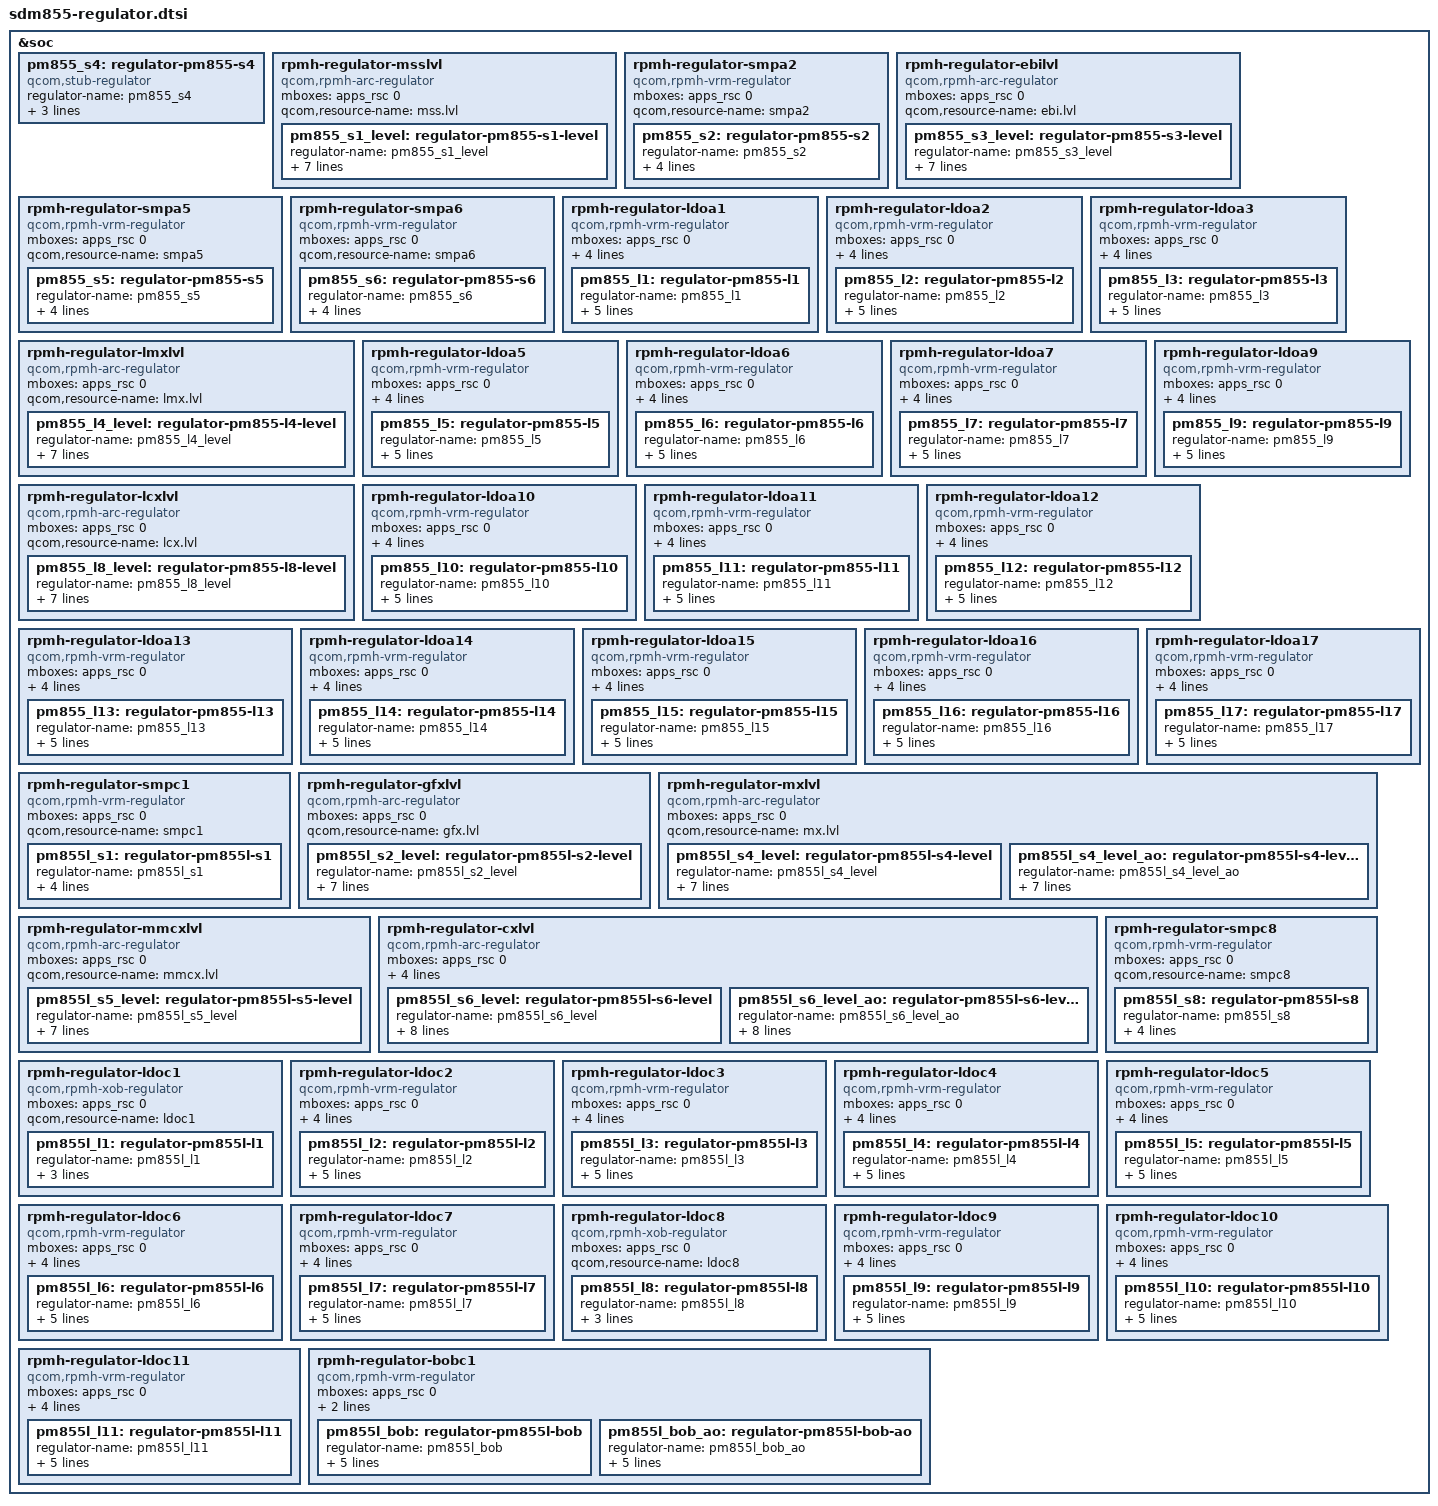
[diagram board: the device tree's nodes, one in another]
/* Copyright (c) 2017-2018, The Linux Foundation. All rights reserved.
 *
 * This program is free software; you can redistribute it and/or modify
 * it under the terms of the GNU General Public License version 2 and
 * only version 2 as published by the Free Software Foundation.
 *
 * This program is distributed in the hope that it will be useful,
 * but WITHOUT ANY WARRANTY; without even the implied warranty of
 * MERCHANTABILITY or FITNESS FOR A PARTICULAR PURPOSE.  See the
 * GNU General Public License for more details.
 */

#include <dt-bindings/regulator/qcom,rpmh-regulator.h>


&soc {
	/* Stub regulators */

	/*
	 * RPMh does not provide support for PM855 S4 because it is always-on
	 * at 1.8 V in auto mode.  Therefore, use a stub regulator for S4.
	 */
	pm855_s4: regulator-pm855-s4 {
		compatible = "qcom,stub-regulator";
		regulator-name = "pm855_s4";
		qcom,hpm-min-load = <100000>;
		regulator-min-microvolt = <1800000>;
		regulator-max-microvolt = <1800000>;
	};
};

&soc {
	/* RPMh regulators: */

	/* PM855 S1 = VDD_MODEM supply */
	rpmh-regulator-msslvl {
		compatible = "qcom,rpmh-arc-regulator";
		mboxes = <&apps_rsc 0>;
		qcom,resource-name = "mss.lvl";
		pm855_s1_level: regulator-pm855-s1-level {
			regulator-name = "pm855_s1_level";
			qcom,set = <RPMH_REGULATOR_SET_ALL>;
			regulator-min-microvolt
				= <RPMH_REGULATOR_LEVEL_RETENTION>;
			regulator-max-microvolt
				= <RPMH_REGULATOR_LEVEL_MAX>;
			qcom,init-voltage-level
				= <RPMH_REGULATOR_LEVEL_RETENTION>;
		};
	};

	rpmh-regulator-smpa2 {
		compatible = "qcom,rpmh-vrm-regulator";
		mboxes = <&apps_rsc 0>;
		qcom,resource-name = "smpa2";
		pm855_s2: regulator-pm855-s2 {
			regulator-name = "pm855_s2";
			qcom,set = <RPMH_REGULATOR_SET_ALL>;
			regulator-min-microvolt = <600000>;
			regulator-max-microvolt = <600000>;
			qcom,init-voltage = <600000>;
		};
	};

	/* PM855 S3 = VDD_EBI supply */
	rpmh-regulator-ebilvl {
		compatible = "qcom,rpmh-arc-regulator";
		mboxes = <&apps_rsc 0>;
		qcom,resource-name = "ebi.lvl";
		pm855_s3_level: regulator-pm855-s3-level {
			regulator-name = "pm855_s3_level";
			qcom,set = <RPMH_REGULATOR_SET_ALL>;
			regulator-min-microvolt
				= <RPMH_REGULATOR_LEVEL_RETENTION>;
			regulator-max-microvolt
				= <RPMH_REGULATOR_LEVEL_MAX>;
			qcom,init-voltage-level
				= <RPMH_REGULATOR_LEVEL_RETENTION>;
		};
	};

	rpmh-regulator-smpa5 {
		compatible = "qcom,rpmh-vrm-regulator";
		mboxes = <&apps_rsc 0>;
		qcom,resource-name = "smpa5";
		pm855_s5: regulator-pm855-s5 {
			regulator-name = "pm855_s5";
			qcom,set = <RPMH_REGULATOR_SET_ALL>;
			regulator-min-microvolt = <1904000>;
			regulator-max-microvolt = <2040000>;
			qcom,init-voltage = <1904000>;
		};
	};

	rpmh-regulator-smpa6 {
		compatible = "qcom,rpmh-vrm-regulator";
		mboxes = <&apps_rsc 0>;
		qcom,resource-name = "smpa6";
		pm855_s6: regulator-pm855-s6 {
			regulator-name = "pm855_s6";
			qcom,set = <RPMH_REGULATOR_SET_ALL>;
			regulator-min-microvolt = <920000>;
			regulator-max-microvolt = <1128000>;
			qcom,init-voltage = <920000>;
		};
	};

	rpmh-regulator-ldoa1 {
		compatible = "qcom,rpmh-vrm-regulator";
		mboxes = <&apps_rsc 0>;
		qcom,resource-name = "ldoa1";
		qcom,supported-modes =
			<RPMH_REGULATOR_MODE_LDO_LPM
			 RPMH_REGULATOR_MODE_LDO_HPM>;
		qcom,mode-threshold-currents = <0 1>;
		pm855_l1: regulator-pm855-l1 {
			regulator-name = "pm855_l1";
			qcom,set = <RPMH_REGULATOR_SET_ALL>;
			regulator-min-microvolt = <752000>;
			regulator-max-microvolt = <752000>;
			qcom,init-voltage = <752000>;
			qcom,init-mode = <RPMH_REGULATOR_MODE_LDO_LPM>;
		};
	};

	rpmh-regulator-ldoa2 {
		compatible = "qcom,rpmh-vrm-regulator";
		mboxes = <&apps_rsc 0>;
		qcom,resource-name = "ldoa2";
		qcom,supported-modes =
			<RPMH_REGULATOR_MODE_LDO_LPM
			 RPMH_REGULATOR_MODE_LDO_HPM>;
		qcom,mode-threshold-currents = <0 10000>;
		pm855_l2: regulator-pm855-l2 {
			regulator-name = "pm855_l2";
			qcom,set = <RPMH_REGULATOR_SET_ALL>;
			regulator-min-microvolt = <3072000>;
			regulator-max-microvolt = <3072000>;
			qcom,init-voltage = <3072000>;
			qcom,init-mode = <RPMH_REGULATOR_MODE_LDO_LPM>;
		};
	};

	rpmh-regulator-ldoa3 {
		compatible = "qcom,rpmh-vrm-regulator";
		mboxes = <&apps_rsc 0>;
		qcom,resource-name = "ldoa3";
		qcom,supported-modes =
			<RPMH_REGULATOR_MODE_LDO_LPM
			 RPMH_REGULATOR_MODE_LDO_HPM>;
		qcom,mode-threshold-currents = <0 1>;
		pm855_l3: regulator-pm855-l3 {
			regulator-name = "pm855_l3";
			qcom,set = <RPMH_REGULATOR_SET_ALL>;
			regulator-min-microvolt = <480000>;
			regulator-max-microvolt = <932000>;
			qcom,init-voltage = <480000>;
			qcom,init-mode = <RPMH_REGULATOR_MODE_LDO_LPM>;
		};
	};

	/* PM855 L4 = VDD_SSC_MX supply */
	rpmh-regulator-lmxlvl {
		compatible = "qcom,rpmh-arc-regulator";
		mboxes = <&apps_rsc 0>;
		qcom,resource-name = "lmx.lvl";
		pm855_l4_level: regulator-pm855-l4-level {
			regulator-name = "pm855_l4_level";
			qcom,set = <RPMH_REGULATOR_SET_ALL>;
			regulator-min-microvolt =
				<RPMH_REGULATOR_LEVEL_RETENTION>;
			regulator-max-microvolt =
				<RPMH_REGULATOR_LEVEL_MAX>;
			qcom,init-voltage-level
				= <RPMH_REGULATOR_LEVEL_RETENTION>;
		};
	};

	rpmh-regulator-ldoa5 {
		compatible = "qcom,rpmh-vrm-regulator";
		mboxes = <&apps_rsc 0>;
		qcom,resource-name = "ldoa5";
		qcom,supported-modes =
			<RPMH_REGULATOR_MODE_LDO_LPM
			 RPMH_REGULATOR_MODE_LDO_HPM>;
		qcom,mode-threshold-currents = <0 1>;
		pm855_l5: regulator-pm855-l5 {
			regulator-name = "pm855_l5";
			qcom,set = <RPMH_REGULATOR_SET_ALL>;
			regulator-min-microvolt = <880000>;
			regulator-max-microvolt = <880000>;
			qcom,init-voltage = <880000>;
			qcom,init-mode = <RPMH_REGULATOR_MODE_LDO_LPM>;
		};
	};

	rpmh-regulator-ldoa6 {
		compatible = "qcom,rpmh-vrm-regulator";
		mboxes = <&apps_rsc 0>;
		qcom,resource-name = "ldoa6";
		qcom,supported-modes =
			<RPMH_REGULATOR_MODE_LDO_LPM
			 RPMH_REGULATOR_MODE_LDO_HPM>;
		qcom,mode-threshold-currents = <0 10000>;
		pm855_l6: regulator-pm855-l6 {
			regulator-name = "pm855_l6";
			qcom,set = <RPMH_REGULATOR_SET_ALL>;
			regulator-min-microvolt = <1200000>;
			regulator-max-microvolt = <1200000>;
			qcom,init-voltage = <1200000>;
			qcom,init-mode = <RPMH_REGULATOR_MODE_LDO_LPM>;
		};
	};

	rpmh-regulator-ldoa7 {
		compatible = "qcom,rpmh-vrm-regulator";
		mboxes = <&apps_rsc 0>;
		qcom,resource-name = "ldoa7";
		qcom,supported-modes =
			<RPMH_REGULATOR_MODE_LDO_LPM
			 RPMH_REGULATOR_MODE_LDO_HPM>;
		qcom,mode-threshold-currents = <0 1>;
		pm855_l7: regulator-pm855-l7 {
			regulator-name = "pm855_l7";
			qcom,set = <RPMH_REGULATOR_SET_ALL>;
			regulator-min-microvolt = <1800000>;
			regulator-max-microvolt = <1800000>;
			qcom,init-voltage = <1800000>;
			qcom,init-mode = <RPMH_REGULATOR_MODE_LDO_LPM>;
		};
	};

	/* PM855 L8 = VDD_SSC_CX supply */
	rpmh-regulator-lcxlvl {
		compatible = "qcom,rpmh-arc-regulator";
		mboxes = <&apps_rsc 0>;
		qcom,resource-name = "lcx.lvl";
		pm855_l8_level: regulator-pm855-l8-level {
			regulator-name = "pm855_l8_level";
			qcom,set = <RPMH_REGULATOR_SET_ALL>;
			regulator-min-microvolt
				= <RPMH_REGULATOR_LEVEL_RETENTION>;
			regulator-max-microvolt
				= <RPMH_REGULATOR_LEVEL_MAX>;
			qcom,init-voltage-level
				= <RPMH_REGULATOR_LEVEL_RETENTION>;
		};
	};

	rpmh-regulator-ldoa9 {
		compatible = "qcom,rpmh-vrm-regulator";
		mboxes = <&apps_rsc 0>;
		qcom,resource-name = "ldoa9";
		qcom,supported-modes =
			<RPMH_REGULATOR_MODE_LDO_LPM
			 RPMH_REGULATOR_MODE_LDO_HPM>;
		qcom,mode-threshold-currents = <0 30000>;
		pm855_l9: regulator-pm855-l9 {
			regulator-name = "pm855_l9";
			qcom,set = <RPMH_REGULATOR_SET_ALL>;
			regulator-min-microvolt = <1200000>;
			regulator-max-microvolt = <1200000>;
			qcom,init-voltage = <1200000>;
			qcom,init-mode = <RPMH_REGULATOR_MODE_LDO_LPM>;
		};
	};

	rpmh-regulator-ldoa10 {
		compatible = "qcom,rpmh-vrm-regulator";
		mboxes = <&apps_rsc 0>;
		qcom,resource-name = "ldoa10";
		qcom,supported-modes =
			<RPMH_REGULATOR_MODE_LDO_LPM
			 RPMH_REGULATOR_MODE_LDO_HPM>;
		qcom,mode-threshold-currents = <0 10000>;
		pm855_l10: regulator-pm855-l10 {
			regulator-name = "pm855_l10";
			qcom,set = <RPMH_REGULATOR_SET_ALL>;
			regulator-min-microvolt = <2504000>;
			regulator-max-microvolt = <2960000>;
			qcom,init-voltage = <2504000>;
			qcom,init-mode = <RPMH_REGULATOR_MODE_LDO_LPM>;
		};
	};

	rpmh-regulator-ldoa11 {
		compatible = "qcom,rpmh-vrm-regulator";
		mboxes = <&apps_rsc 0>;
		qcom,resource-name = "ldoa11";
		qcom,supported-modes =
			<RPMH_REGULATOR_MODE_LDO_LPM
			 RPMH_REGULATOR_MODE_LDO_HPM>;
		qcom,mode-threshold-currents = <0 1>;
		pm855_l11: regulator-pm855-l11 {
			regulator-name = "pm855_l11";
			qcom,set = <RPMH_REGULATOR_SET_ALL>;
			regulator-min-microvolt = <800000>;
			regulator-max-microvolt = <800000>;
			qcom,init-voltage = <800000>;
			qcom,init-mode = <RPMH_REGULATOR_MODE_LDO_LPM>;
		};
	};

	rpmh-regulator-ldoa12 {
		compatible = "qcom,rpmh-vrm-regulator";
		mboxes = <&apps_rsc 0>;
		qcom,resource-name = "ldoa12";
		qcom,supported-modes =
			<RPMH_REGULATOR_MODE_LDO_LPM
			 RPMH_REGULATOR_MODE_LDO_HPM>;
		qcom,mode-threshold-currents = <0 1>;
		pm855_l12: regulator-pm855-l12 {
			regulator-name = "pm855_l12";
			qcom,set = <RPMH_REGULATOR_SET_ALL>;
			regulator-min-microvolt = <1800000>;
			regulator-max-microvolt = <1800000>;
			qcom,init-voltage = <1800000>;
			qcom,init-mode = <RPMH_REGULATOR_MODE_LDO_LPM>;
		};
	};

	rpmh-regulator-ldoa13 {
		compatible = "qcom,rpmh-vrm-regulator";
		mboxes = <&apps_rsc 0>;
		qcom,resource-name = "ldoa13";
		qcom,supported-modes =
			<RPMH_REGULATOR_MODE_LDO_LPM
			 RPMH_REGULATOR_MODE_LDO_HPM>;
		qcom,mode-threshold-currents = <0 1>;
		pm855_l13: regulator-pm855-l13 {
			regulator-name = "pm855_l13";
			qcom,set = <RPMH_REGULATOR_SET_ALL>;
			regulator-min-microvolt = <2704000>;
			regulator-max-microvolt = <2704000>;
			qcom,init-voltage = <2704000>;
			qcom,init-mode = <RPMH_REGULATOR_MODE_LDO_LPM>;
		};
	};

	rpmh-regulator-ldoa14 {
		compatible = "qcom,rpmh-vrm-regulator";
		mboxes = <&apps_rsc 0>;
		qcom,resource-name = "ldoa14";
		qcom,supported-modes =
			<RPMH_REGULATOR_MODE_LDO_LPM
			 RPMH_REGULATOR_MODE_LDO_HPM>;
		qcom,mode-threshold-currents = <0 10000>;
		pm855_l14: regulator-pm855-l14 {
			regulator-name = "pm855_l14";
			qcom,set = <RPMH_REGULATOR_SET_ALL>;
			regulator-min-microvolt = <1800000>;
			regulator-max-microvolt = <1880000>;
			qcom,init-voltage = <1800000>;
			qcom,init-mode = <RPMH_REGULATOR_MODE_LDO_LPM>;
		};
	};

	rpmh-regulator-ldoa15 {
		compatible = "qcom,rpmh-vrm-regulator";
		mboxes = <&apps_rsc 0>;
		qcom,resource-name = "ldoa15";
		qcom,supported-modes =
			<RPMH_REGULATOR_MODE_LDO_LPM
			 RPMH_REGULATOR_MODE_LDO_HPM>;
		qcom,mode-threshold-currents = <0 1>;
		pm855_l15: regulator-pm855-l15 {
			regulator-name = "pm855_l15";
			qcom,set = <RPMH_REGULATOR_SET_ALL>;
			regulator-min-microvolt = <1704000>;
			regulator-max-microvolt = <1704000>;
			qcom,init-voltage = <1704000>;
			qcom,init-mode = <RPMH_REGULATOR_MODE_LDO_LPM>;
		};
	};

	rpmh-regulator-ldoa16 {
		compatible = "qcom,rpmh-vrm-regulator";
		mboxes = <&apps_rsc 0>;
		qcom,resource-name = "ldoa16";
		qcom,supported-modes =
			<RPMH_REGULATOR_MODE_LDO_LPM
			 RPMH_REGULATOR_MODE_LDO_HPM>;
		qcom,mode-threshold-currents = <0 1>;
		pm855_l16: regulator-pm855-l16 {
			regulator-name = "pm855_l16";
			qcom,set = <RPMH_REGULATOR_SET_ALL>;
			regulator-min-microvolt = <2704000>;
			regulator-max-microvolt = <2960000>;
			qcom,init-voltage = <2704000>;
			qcom,init-mode = <RPMH_REGULATOR_MODE_LDO_LPM>;
		};
	};

	rpmh-regulator-ldoa17 {
		compatible = "qcom,rpmh-vrm-regulator";
		mboxes = <&apps_rsc 0>;
		qcom,resource-name = "ldoa17";
		qcom,supported-modes =
			<RPMH_REGULATOR_MODE_LDO_LPM
			 RPMH_REGULATOR_MODE_LDO_HPM>;
		qcom,mode-threshold-currents = <0 1>;
		pm855_l17: regulator-pm855-l17 {
			regulator-name = "pm855_l17";
			qcom,set = <RPMH_REGULATOR_SET_ALL>;
			regulator-min-microvolt = <2856000>;
			regulator-max-microvolt = <3008000>;
			qcom,init-voltage = <2856000>;
			qcom,init-mode = <RPMH_REGULATOR_MODE_LDO_LPM>;
		};
	};

	rpmh-regulator-smpc1 {
		compatible = "qcom,rpmh-vrm-regulator";
		mboxes = <&apps_rsc 0>;
		qcom,resource-name = "smpc1";
		pm855l_s1: regulator-pm855l-s1 {
			regulator-name = "pm855l_s1";
			qcom,set = <RPMH_REGULATOR_SET_ALL>;
			regulator-min-microvolt = <1128000>;
			regulator-max-microvolt = <1128000>;
			qcom,init-voltage = <1128000>;
		};
	};

	/* PM855L S2 + S3 = 2 phase VDD_GFX supply */
	rpmh-regulator-gfxlvl {
		compatible = "qcom,rpmh-arc-regulator";
		mboxes = <&apps_rsc 0>;
		qcom,resource-name = "gfx.lvl";
		pm855l_s2_level: regulator-pm855l-s2-level {
			regulator-name = "pm855l_s2_level";
			qcom,set = <RPMH_REGULATOR_SET_ALL>;
			regulator-min-microvolt
				= <RPMH_REGULATOR_LEVEL_RETENTION>;
			regulator-max-microvolt
				= <RPMH_REGULATOR_LEVEL_MAX>;
			qcom,init-voltage-level
				= <RPMH_REGULATOR_LEVEL_RETENTION>;
		};
	};

	/* PM855L S4 = VDD_MX supply */
	rpmh-regulator-mxlvl {
		compatible = "qcom,rpmh-arc-regulator";
		mboxes = <&apps_rsc 0>;
		qcom,resource-name = "mx.lvl";
		pm855l_s4_level: regulator-pm855l-s4-level {
			regulator-name = "pm855l_s4_level";
			qcom,set = <RPMH_REGULATOR_SET_ALL>;
			regulator-min-microvolt
				= <RPMH_REGULATOR_LEVEL_RETENTION>;
			regulator-max-microvolt
				= <RPMH_REGULATOR_LEVEL_MAX>;
			qcom,init-voltage-level
				= <RPMH_REGULATOR_LEVEL_RETENTION>;
		};

		pm855l_s4_level_ao: regulator-pm855l-s4-level-ao {
			regulator-name = "pm855l_s4_level_ao";
			qcom,set = <RPMH_REGULATOR_SET_ACTIVE>;
			regulator-min-microvolt
				= <RPMH_REGULATOR_LEVEL_RETENTION>;
			regulator-max-microvolt
				= <RPMH_REGULATOR_LEVEL_MAX>;
			qcom,init-voltage-level
				= <RPMH_REGULATOR_LEVEL_RETENTION>;
		};
	};

	/* PM855L S5 = VDD_MM_CX supply */
	rpmh-regulator-mmcxlvl {
		compatible = "qcom,rpmh-arc-regulator";
		mboxes = <&apps_rsc 0>;
		qcom,resource-name = "mmcx.lvl";
		pm855l_s5_level: regulator-pm855l-s5-level {
			regulator-name = "pm855l_s5_level";
			qcom,set = <RPMH_REGULATOR_SET_ALL>;
			regulator-min-microvolt
				= <RPMH_REGULATOR_LEVEL_LOW_SVS>;
			regulator-max-microvolt
				= <RPMH_REGULATOR_LEVEL_MAX>;
			qcom,init-voltage-level
				= <RPMH_REGULATOR_LEVEL_LOW_SVS>;
		};
	};

	/* PM855L S6 + S7 = VDD_CX supply */
	rpmh-regulator-cxlvl {
		compatible = "qcom,rpmh-arc-regulator";
		mboxes = <&apps_rsc 0>;
		qcom,resource-name = "cx.lvl";
		pm855l_s6_level-parent-supply = <&pm855l_s4_level>;
		pm855l_s6_level_ao-parent-supply = <&pm855l_s4_level_ao>;
		pm855l_s6_level: regulator-pm855l-s6-level {
			regulator-name = "pm855l_s6_level";
			qcom,set = <RPMH_REGULATOR_SET_ALL>;
			regulator-min-microvolt
				= <RPMH_REGULATOR_LEVEL_RETENTION>;
			regulator-max-microvolt
				= <RPMH_REGULATOR_LEVEL_MAX>;
			qcom,init-voltage-level
				= <RPMH_REGULATOR_LEVEL_RETENTION>;
			qcom,min-dropout-voltage-level = <(-1)>;
		};

		pm855l_s6_level_ao: regulator-pm855l-s6-level-ao {
			regulator-name = "pm855l_s6_level_ao";
			qcom,set = <RPMH_REGULATOR_SET_ACTIVE>;
			regulator-min-microvolt
				= <RPMH_REGULATOR_LEVEL_RETENTION>;
			regulator-max-microvolt
				= <RPMH_REGULATOR_LEVEL_MAX>;
			qcom,init-voltage-level
				= <RPMH_REGULATOR_LEVEL_RETENTION>;
			qcom,min-dropout-voltage-level = <(-1)>;
		};
	};

	rpmh-regulator-smpc8 {
		compatible = "qcom,rpmh-vrm-regulator";
		mboxes = <&apps_rsc 0>;
		qcom,resource-name = "smpc8";
		pm855l_s8: regulator-pm855l-s8 {
			regulator-name = "pm855l_s8";
			qcom,set = <RPMH_REGULATOR_SET_ALL>;
			regulator-min-microvolt = <1352000>;
			regulator-max-microvolt = <1352000>;
			qcom,init-voltage = <1352000>;
		};
	};

	rpmh-regulator-ldoc1 {
		compatible = "qcom,rpmh-xob-regulator";
		mboxes = <&apps_rsc 0>;
		qcom,resource-name = "ldoc1";
		pm855l_l1: regulator-pm855l-l1 {
			regulator-name = "pm855l_l1";
			qcom,set = <RPMH_REGULATOR_SET_ALL>;
			regulator-min-microvolt = <1800000>;
			regulator-max-microvolt = <1800000>;
		};
	};

	rpmh-regulator-ldoc2 {
		compatible = "qcom,rpmh-vrm-regulator";
		mboxes = <&apps_rsc 0>;
		qcom,resource-name = "ldoc2";
		qcom,supported-modes =
			<RPMH_REGULATOR_MODE_LDO_LPM
			 RPMH_REGULATOR_MODE_LDO_HPM>;
		qcom,mode-threshold-currents = <0 1>;
		pm855l_l2: regulator-pm855l-l2 {
			regulator-name = "pm855l_l2";
			qcom,set = <RPMH_REGULATOR_SET_ALL>;
			regulator-min-microvolt = <1304000>;
			regulator-max-microvolt = <1304000>;
			qcom,init-voltage = <1304000>;
			qcom,init-mode = <RPMH_REGULATOR_MODE_LDO_LPM>;
		};
	};

	rpmh-regulator-ldoc3 {
		compatible = "qcom,rpmh-vrm-regulator";
		mboxes = <&apps_rsc 0>;
		qcom,resource-name = "ldoc3";
		qcom,supported-modes =
			<RPMH_REGULATOR_MODE_LDO_LPM
			 RPMH_REGULATOR_MODE_LDO_HPM>;
		qcom,mode-threshold-currents = <0 1>;
		pm855l_l3: regulator-pm855l-l3 {
			regulator-name = "pm855l_l3";
			qcom,set = <RPMH_REGULATOR_SET_ALL>;
			regulator-min-microvolt = <1200000>;
			regulator-max-microvolt = <1200000>;
			qcom,init-voltage = <1200000>;
			qcom,init-mode = <RPMH_REGULATOR_MODE_LDO_LPM>;
		};
	};

	rpmh-regulator-ldoc4 {
		compatible = "qcom,rpmh-vrm-regulator";
		mboxes = <&apps_rsc 0>;
		qcom,resource-name = "ldoc4";
		qcom,supported-modes =
			<RPMH_REGULATOR_MODE_LDO_LPM
			 RPMH_REGULATOR_MODE_LDO_HPM>;
		qcom,mode-threshold-currents = <0 1>;
		pm855l_l4: regulator-pm855l-l4 {
			regulator-name = "pm855l_l4";
			qcom,set = <RPMH_REGULATOR_SET_ALL>;
			regulator-min-microvolt = <1704000>;
			regulator-max-microvolt = <2928000>;
			qcom,init-voltage = <1704000>;
			qcom,init-mode = <RPMH_REGULATOR_MODE_LDO_LPM>;
		};
	};

	rpmh-regulator-ldoc5 {
		compatible = "qcom,rpmh-vrm-regulator";
		mboxes = <&apps_rsc 0>;
		qcom,resource-name = "ldoc5";
		qcom,supported-modes =
			<RPMH_REGULATOR_MODE_LDO_LPM
			 RPMH_REGULATOR_MODE_LDO_HPM>;
		qcom,mode-threshold-currents = <0 1>;
		pm855l_l5: regulator-pm855l-l5 {
			regulator-name = "pm855l_l5";
			qcom,set = <RPMH_REGULATOR_SET_ALL>;
			regulator-min-microvolt = <1704000>;
			regulator-max-microvolt = <2928000>;
			qcom,init-voltage = <1704000>;
			qcom,init-mode = <RPMH_REGULATOR_MODE_LDO_LPM>;
		};
	};

	rpmh-regulator-ldoc6 {
		compatible = "qcom,rpmh-vrm-regulator";
		mboxes = <&apps_rsc 0>;
		qcom,resource-name = "ldoc6";
		qcom,supported-modes =
			<RPMH_REGULATOR_MODE_LDO_LPM
			 RPMH_REGULATOR_MODE_LDO_HPM>;
		qcom,mode-threshold-currents = <0 1>;
		pm855l_l6: regulator-pm855l-l6 {
			regulator-name = "pm855l_l6";
			qcom,set = <RPMH_REGULATOR_SET_ALL>;
			regulator-min-microvolt = <1800000>;
			regulator-max-microvolt = <2960000>;
			qcom,init-voltage = <1800000>;
			qcom,init-mode = <RPMH_REGULATOR_MODE_LDO_LPM>;
		};
	};

	rpmh-regulator-ldoc7 {
		compatible = "qcom,rpmh-vrm-regulator";
		mboxes = <&apps_rsc 0>;
		qcom,resource-name = "ldoc7";
		qcom,supported-modes =
			<RPMH_REGULATOR_MODE_LDO_LPM
			 RPMH_REGULATOR_MODE_LDO_HPM>;
		qcom,mode-threshold-currents = <0 1>;
		pm855l_l7: regulator-pm855l-l7 {
			regulator-name = "pm855l_l7";
			qcom,set = <RPMH_REGULATOR_SET_ALL>;
			regulator-min-microvolt = <2856000>;
			regulator-max-microvolt = <3104000>;
			qcom,init-voltage = <2856000>;
			qcom,init-mode = <RPMH_REGULATOR_MODE_LDO_LPM>;
		};
	};

	rpmh-regulator-ldoc8 {
		compatible = "qcom,rpmh-xob-regulator";
		mboxes = <&apps_rsc 0>;
		qcom,resource-name = "ldoc8";
		pm855l_l8: regulator-pm855l-l8 {
			regulator-name = "pm855l_l8";
			qcom,set = <RPMH_REGULATOR_SET_ALL>;
			regulator-min-microvolt = <1800000>;
			regulator-max-microvolt = <1800000>;
		};
	};

	rpmh-regulator-ldoc9 {
		compatible = "qcom,rpmh-vrm-regulator";
		mboxes = <&apps_rsc 0>;
		qcom,resource-name = "ldoc9";
		qcom,supported-modes =
			<RPMH_REGULATOR_MODE_LDO_LPM
			 RPMH_REGULATOR_MODE_LDO_HPM>;
		qcom,mode-threshold-currents = <0 10000>;
		pm855l_l9: regulator-pm855l-l9 {
			regulator-name = "pm855l_l9";
			qcom,set = <RPMH_REGULATOR_SET_ALL>;
			regulator-min-microvolt = <2704000>;
			regulator-max-microvolt = <2960000>;
			qcom,init-voltage = <2704000>;
			qcom,init-mode = <RPMH_REGULATOR_MODE_LDO_LPM>;
		};
	};

	rpmh-regulator-ldoc10 {
		compatible = "qcom,rpmh-vrm-regulator";
		mboxes = <&apps_rsc 0>;
		qcom,resource-name = "ldoc10";
		qcom,supported-modes =
			<RPMH_REGULATOR_MODE_LDO_LPM
			 RPMH_REGULATOR_MODE_LDO_HPM>;
		qcom,mode-threshold-currents = <0 1>;
		pm855l_l10: regulator-pm855l-l10 {
			regulator-name = "pm855l_l10";
			qcom,set = <RPMH_REGULATOR_SET_ALL>;
			regulator-min-microvolt = <3000000>;
			regulator-max-microvolt = <3312000>;
			qcom,init-voltage = <3000000>;
			qcom,init-mode = <RPMH_REGULATOR_MODE_LDO_LPM>;
		};
	};

	rpmh-regulator-ldoc11 {
		compatible = "qcom,rpmh-vrm-regulator";
		mboxes = <&apps_rsc 0>;
		qcom,resource-name = "ldoc11";
		qcom,supported-modes =
			<RPMH_REGULATOR_MODE_LDO_LPM
			 RPMH_REGULATOR_MODE_LDO_HPM>;
		qcom,mode-threshold-currents = <0 1>;
		pm855l_l11: regulator-pm855l-l11 {
			regulator-name = "pm855l_l11";
			qcom,set = <RPMH_REGULATOR_SET_ALL>;
			regulator-min-microvolt = <3000000>;
			regulator-max-microvolt = <3312000>;
			qcom,init-voltage = <3000000>;
			qcom,init-mode = <RPMH_REGULATOR_MODE_LDO_LPM>;
		};
	};

	rpmh-regulator-bobc1 {
		compatible = "qcom,rpmh-vrm-regulator";
		mboxes = <&apps_rsc 0>;
		qcom,resource-name = "bobc1";
		qcom,send-defaults;

		pm855l_bob: regulator-pm855l-bob {
			regulator-name = "pm855l_bob";
			qcom,set = <RPMH_REGULATOR_SET_ALL>;
			regulator-min-microvolt = <3008000>;
			regulator-max-microvolt = <4000000>;
			qcom,init-voltage = <3312000>;
			qcom,init-mode = <RPMH_REGULATOR_MODE_BOB_PASS>;
		};

		pm855l_bob_ao: regulator-pm855l-bob-ao {
			regulator-name = "pm855l_bob_ao";
			qcom,set = <RPMH_REGULATOR_SET_ACTIVE>;
			regulator-min-microvolt = <3008000>;
			regulator-max-microvolt = <4000000>;
			qcom,init-voltage = <3008000>;
			qcom,init-mode = <RPMH_REGULATOR_MODE_BOB_AUTO>;
		};
	};
};
